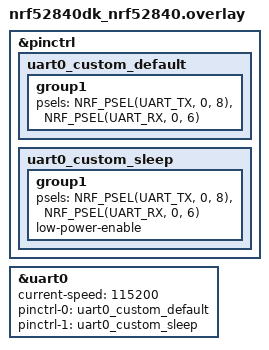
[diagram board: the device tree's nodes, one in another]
&pinctrl {
    uart0_custom_default: uart0_custom_default {
        group1 {
            psels = <NRF_PSEL(UART_TX, 0, 8)>, <NRF_PSEL(UART_RX, 0, 6)>;
        };
    };

    uart0_custom_sleep: uart0_custom_sleep {
        group1 {
            psels = <NRF_PSEL(UART_TX, 0, 8)>, <NRF_PSEL(UART_RX, 0, 6)>;
            low-power-enable;
        };
    };
};

&uart0 {
    status = "okay";
    current-speed = <115200>;
    pinctrl-0 = <&uart0_custom_default>;
    pinctrl-1 = <&uart0_custom_sleep>;
    pinctrl-names = "default", "sleep";
};
